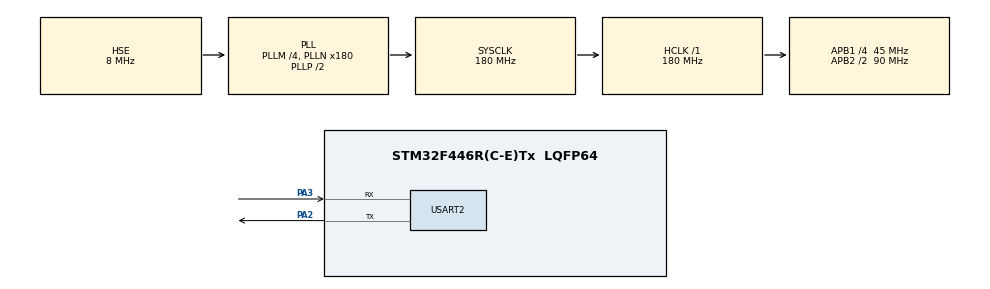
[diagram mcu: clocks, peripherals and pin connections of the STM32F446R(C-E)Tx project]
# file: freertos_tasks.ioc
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FREERTOS.Tasks01=Task1,0,128,StartTask1,Default,NULL,Dynamic,NULL,NULL;Task2,0,128,StartTask2,Default,NULL,Dynamic,NULL,NULL;Task3,0,128,StartTask3,Default,NULL,Dynamic,NULL,NULL
Mcu.Family=STM32F4
Mcu.Name=STM32F446R(C-E)Tx
Mcu.Package=LQFP64
NVIC.PriorityGroup=NVIC_PRIORITYGROUP_4
NVIC.TIM1_UP_TIM10_IRQn=true\:15\:0\:false\:false\:true\:false\:false\:true
NVIC.TimeBase=TIM1_UP_TIM10_IRQn
NVIC.TimeBaseIP=TIM1
PA2.Mode=Asynchronous
PA2.Signal=USART2_TX
PA3.Mode=Asynchronous
PA3.Signal=USART2_RX
PH0-OSC_IN.Mode=HSE-External-Oscillator
PH0-OSC_IN.Signal=RCC_OSC_IN
PH1-OSC_OUT.Mode=HSE-External-Oscillator
PH1-OSC_OUT.Signal=RCC_OSC_OUT
ProjectManager.HeapSize=0x200
ProjectManager.StackSize=0x400
ProjectManager.TargetToolchain=STM32CubeIDE
RCC.48MHZClocksFreq_Value=84000000
RCC.AHBFreq_Value=180000000
RCC.APB1CLKDivider=RCC_HCLK_DIV4
RCC.APB1Freq_Value=45000000
RCC.APB1TimFreq_Value=90000000
RCC.APB2CLKDivider=RCC_HCLK_DIV2
RCC.APB2Freq_Value=90000000
RCC.APB2TimFreq_Value=180000000
RCC.CortexFreq_Value=180000000
RCC.FLatency-AdvancedSettings=FLASH_LATENCY_5
RCC.HCLKFreq_Value=180000000
RCC.HSE_VALUE=8000000
RCC.HSI_VALUE=16000000
RCC.PLLM=4
RCC.PLLN=180
RCC.PLLSourceVirtual=RCC_PLLSOURCE_HSE
RCC.SYSCLKFreq_VALUE=180000000
RCC.SYSCLKSource=RCC_SYSCLKSOURCE_PLLCLK
RCC.USBFreq_Value=180000000
RCC.VCOOutputFreq_Value=360000000
USART2.VirtualMode=VM_ASYNC
VP_FREERTOS_VS_CMSIS_V1.Mode=CMSIS_V1
VP_SYS_VS_tim1.Mode=TIM1
board=NUCLEO-F446RE

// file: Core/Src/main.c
/* USER CODE BEGIN Header */
/**
  ******************************************************************************
  * @file           : main.c
  * @brief          : Main program body
  ******************************************************************************
  * @attention
  *
  * <h2><center>&copy; Copyright (c) 2021 STMicroelectronics.
  * All rights reserved.</center></h2>
  *
  * This software component is licensed by ST under BSD 3-Clause license,
  * the "License"; You may not use this file except in compliance with the
  * License. You may obtain a copy of the License at:
  *                        opensource.org/licenses/BSD-3-Clause
  *
  ******************************************************************************
  */
/* USER CODE END Header */
#include "main.h"
#include "cmsis_os.h"

UART_HandleTypeDef huart2;

osThreadId Task1Handle;
osThreadId Task2Handle;
osThreadId Task3Handle;

void SystemClock_Config(void);
static void MX_GPIO_Init(void);
static void MX_USART2_UART_Init(void);
void StartTask1(void const* argument);

/* USER CODE BEGIN PFP */
void StartTask2(void const* argument);
void StartTask3(void const* argument);

/* USER CODE END PFP */

/* USER CODE BEGIN 0 */

void send_task1(void)
{

	uint8_t data[]="Hello from task 1 \n";
	HAL_UART_Transmit(&huart2, data, sizeof(data), 10000);
}

void send_task2(void)
{

	uint8_t data[]="Hello from task 2 \n";
	HAL_UART_Transmit(&huart2, data, sizeof(data), 10000);
}

void send_task3(void)
{

	uint8_t data[]="Hello from task 3 \n";
	HAL_UART_Transmit(&huart2, data, sizeof(data), 10000);
}
/* USER CODE END 0 */

int main(void)
{

  /* MCU Configuration--------------------------------------------------------*/

  /* Reset of all peripherals, Initializes the Flash interface and the Systick. */
  HAL_Init();

  /* Configure the system clock */
  SystemClock_Config();

  /* Initialize all configured peripherals */
  MX_GPIO_Init();
  MX_USART2_UART_Init();

  /* Create the thread(s) */
  /* definition and creation of Task1 */
  osThreadDef(Task1, StartTask1, osPriorityAboveNormal, 0, 128);
  Task1Handle = osThreadCreate(osThread(Task1), NULL);

  /* definition and creation of Task2 */
  osThreadDef(Task2, StartTask2, osPriorityNormal, 0, 128);
  Task2Handle = osThreadCreate(osThread(Task2), NULL);

  /* definition and creation of Task3 */
  osThreadDef(Task3, StartTask3, osPriorityBelowNormal, 0, 128);
  Task3Handle = osThreadCreate(osThread(Task3), NULL);

  /* Start scheduler */
  osKernelStart();

  /* We should never get here as control is now taken by the scheduler */
  /* Infinite loop */
  while (1)
  {

  }
}

void SystemClock_Config(void)
{
  RCC_OscInitTypeDef RCC_OscInitStruct = {0};
  RCC_ClkInitTypeDef RCC_ClkInitStruct = {0};

  /** Configure the main internal regulator output voltage
  */
  __HAL_RCC_PWR_CLK_ENABLE();
  __HAL_PWR_VOLTAGESCALING_CONFIG(PWR_REGULATOR_VOLTAGE_SCALE1);
  /** Initializes the RCC Oscillators according to the specified parameters
  * in the RCC_OscInitTypeDef structure.
  */
  RCC_OscInitStruct.OscillatorType = RCC_OSCILLATORTYPE_HSE;
  RCC_OscInitStruct.HSEState = RCC_HSE_ON;
  RCC_OscInitStruct.PLL.PLLState = RCC_PLL_ON;
  RCC_OscInitStruct.PLL.PLLSource = RCC_PLLSOURCE_HSE;
  RCC_OscInitStruct.PLL.PLLM = 4;
  RCC_OscInitStruct.PLL.PLLN = 180;
  RCC_OscInitStruct.PLL.PLLP = RCC_PLLP_DIV2;
  RCC_OscInitStruct.PLL.PLLQ = 2;
  RCC_OscInitStruct.PLL.PLLR = 2;
  if (HAL_RCC_OscConfig(&RCC_OscInitStruct) != HAL_OK)
  {
    Error_Handler();
  }
  /** Activate the Over-Drive mode
  */
  if (HAL_PWREx_EnableOverDrive() != HAL_OK)
  {
    Error_Handler();
  }
  /** Initializes the CPU, AHB and APB buses clocks
  */
  RCC_ClkInitStruct.ClockType = RCC_CLOCKTYPE_HCLK|RCC_CLOCKTYPE_SYSCLK
                              |RCC_CLOCKTYPE_PCLK1|RCC_CLOCKTYPE_PCLK2;
  RCC_ClkInitStruct.SYSCLKSource = RCC_SYSCLKSOURCE_PLLCLK;
  RCC_ClkInitStruct.AHBCLKDivider = RCC_SYSCLK_DIV1;
  RCC_ClkInitStruct.APB1CLKDivider = RCC_HCLK_DIV4;
  RCC_ClkInitStruct.APB2CLKDivider = RCC_HCLK_DIV2;

  if (HAL_RCC_ClockConfig(&RCC_ClkInitStruct, FLASH_LATENCY_5) != HAL_OK)
  {
    Error_Handler();
  }
}

static void MX_USART2_UART_Init(void)
{

  huart2.Instance = USART2;
  huart2.Init.BaudRate = 115200;
  huart2.Init.WordLength = UART_WORDLENGTH_8B;
  huart2.Init.StopBits = UART_STOPBITS_1;
  huart2.Init.Parity = UART_PARITY_NONE;
  huart2.Init.Mode = UART_MODE_TX_RX;
  huart2.Init.HwFlowCtl = UART_HWCONTROL_NONE;
  huart2.Init.OverSampling = UART_OVERSAMPLING_16;
  if (HAL_UART_Init(&huart2) != HAL_OK)
  {
    Error_Handler();
  }

}

static void MX_GPIO_Init(void)
{

  /* GPIO Ports Clock Enable */
  __HAL_RCC_GPIOH_CLK_ENABLE();
  __HAL_RCC_GPIOA_CLK_ENABLE();

}

void StartTask1(void const * argument)
{
  /* USER CODE BEGIN 5 */
  /* Infinite loop */
  for(;;)
  {
	  send_task1();
    osDelay(1000);
  }
  /* USER CODE END 5 */
}

void StartTask2(void const * argument)
{
  /* USER CODE BEGIN StartTask2 */
  /* Infinite loop */
  for(;;)
  {
	send_task2();
    osDelay(1000);
  }
  /* USER CODE END StartTask2 */
}

void StartTask3(void const * argument)
{
  /* USER CODE BEGIN StartTask3 */
  /* Infinite loop */
  for(;;)
  {
	  send_task3();
    osDelay(1000);
  }
  /* USER CODE END StartTask3 */
}

void HAL_TIM_PeriodElapsedCallback(TIM_HandleTypeDef *htim)
{
  if (htim->Instance == TIM1) {
    HAL_IncTick();
  }
}

void Error_Handler(void)
{
  __disable_irq();
  while (1)
  {
  }
}

/************************ (C) COPYRIGHT STMicroelectronics *****END OF FILE****/
